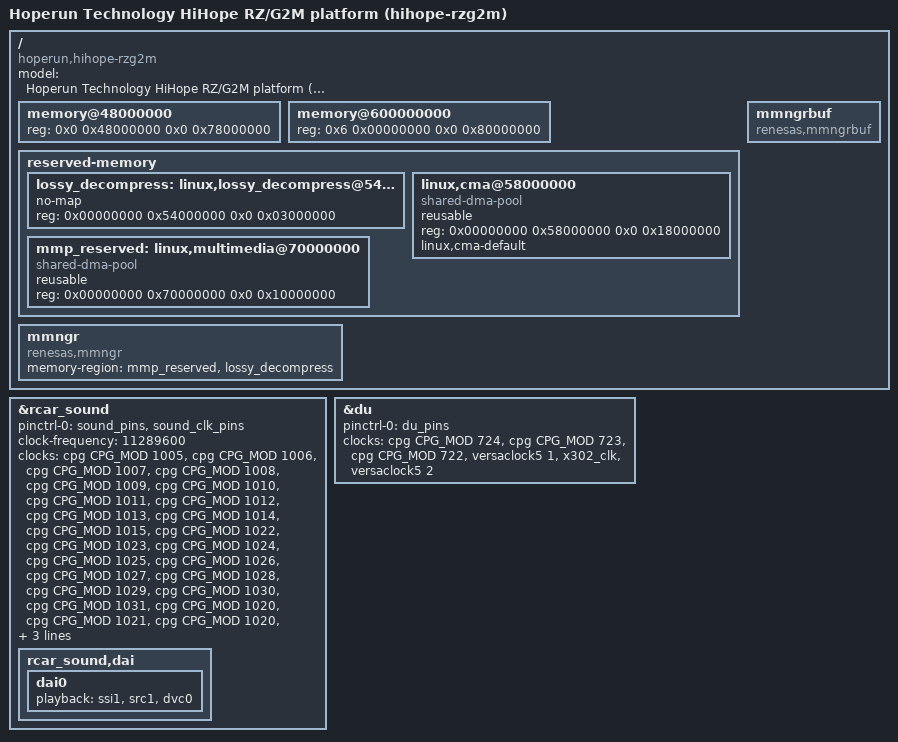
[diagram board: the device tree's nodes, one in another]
// SPDX-License-Identifier: GPL-2.0
/*
 * Device Tree Source for the Hoperun Technology HiHope RZ/G2M platform
 * (hihope-rzg2m)
 *
 * Copyright (C) 2019 Renesas Electronics Corp.
 */

/dts-v1/;
#include "r8a774a1.dtsi"
#include "hihope-common.dtsi"

/ {
	model = "Hoperun Technology HiHope RZ/G2M platform (hihope-rzg2m)";
	compatible = "hoperun,hihope-rzg2m", "renesas,r8a774a1";

	memory@48000000 {
		device_type = "memory";
		/* first 128MB is reserved for secure area. */
		reg = <0x0 0x48000000 0x0 0x78000000>;
	};

	memory@600000000 {
		device_type = "memory";
		reg = <0x6 0x00000000 0x0 0x80000000>;
	};

	reserved-memory {
		#address-cells = <2>;
		#size-cells = <2>;
		ranges;

		/* device specific region for Lossy Decompression */
		lossy_decompress: linux,lossy_decompress@54000000 {
			no-map;
			reg = <0x00000000 0x54000000 0x0 0x03000000>;
		};

		/* global autoconfigured region for contiguous allocations */
		linux,cma@58000000 {
			compatible = "shared-dma-pool";
			reusable;
			reg = <0x00000000 0x58000000 0x0 0x18000000>;
			linux,cma-default;
		};

		/* device specific region for contiguous allocations */
		mmp_reserved: linux,multimedia@70000000 {
			compatible = "shared-dma-pool";
			reusable;
			reg = <0x00000000 0x70000000 0x0 0x10000000>;
		};
	};

	mmngr {
		compatible = "renesas,mmngr";
		memory-region = <&mmp_reserved>, <&lossy_decompress>;
	};

	mmngrbuf {
		compatible = "renesas,mmngrbuf";
	};
};

&rcar_sound {
	pinctrl-0 = <&sound_pins &sound_clk_pins>;
	pinctrl-names = "default";

	/* Single DAI */
	#sound-dai-cells = <0>;

	/* audio_clkout0/1/2/3 */
	#clock-cells = <1>;
	clock-frequency = <11289600>;

	status = "okay";

	clocks = <&cpg CPG_MOD 1005>,
		 <&cpg CPG_MOD 1006>, <&cpg CPG_MOD 1007>,
		 <&cpg CPG_MOD 1008>, <&cpg CPG_MOD 1009>,
		 <&cpg CPG_MOD 1010>, <&cpg CPG_MOD 1011>,
		 <&cpg CPG_MOD 1012>, <&cpg CPG_MOD 1013>,
		 <&cpg CPG_MOD 1014>, <&cpg CPG_MOD 1015>,
		 <&cpg CPG_MOD 1022>, <&cpg CPG_MOD 1023>,
		 <&cpg CPG_MOD 1024>, <&cpg CPG_MOD 1025>,
		 <&cpg CPG_MOD 1026>, <&cpg CPG_MOD 1027>,
		 <&cpg CPG_MOD 1028>, <&cpg CPG_MOD 1029>,
		 <&cpg CPG_MOD 1030>, <&cpg CPG_MOD 1031>,
		 <&cpg CPG_MOD 1020>, <&cpg CPG_MOD 1021>,
		 <&cpg CPG_MOD 1020>, <&cpg CPG_MOD 1021>,
		 <&cpg CPG_MOD 1019>, <&cpg CPG_MOD 1018>,
		 <&audio_clk_a>, <&audio_clk_b>, <&audio_clk_c>,
		 <&cpg CPG_CORE R8A774A1_CLK_S0D4>;

	rcar_sound,dai {
		dai0 {
			playback = <&ssi1 &src1 &dvc0>;
		};
	};
};

&du {
	pinctrl-0 = <&du_pins>;
	pinctrl-names = "default";
	status = "okay";

	clocks = <&cpg CPG_MOD 724>,
		<&cpg CPG_MOD 723>,
		<&cpg CPG_MOD 722>,
		<&versaclock5 1>,
		<&x302_clk>,
		<&versaclock5 2>;
	clock-names = "du.0", "du.1", "du.2",
			"dclkin.0", "dclkin.1", "dclkin.2";
};

